# STM32H5F4xx register map
File version: 1.0
Registers are 32-bit, read-write, reset 0x0 unless marked. A register's access mark holds for its fields unless they carry their own. Offsets are from the block's base; [hi:lo] are bit positions; {n}, {i} and the like mark numbered series.

## HASH
Base 0x420C0400
Same registers: HASH_S 0x520C0400
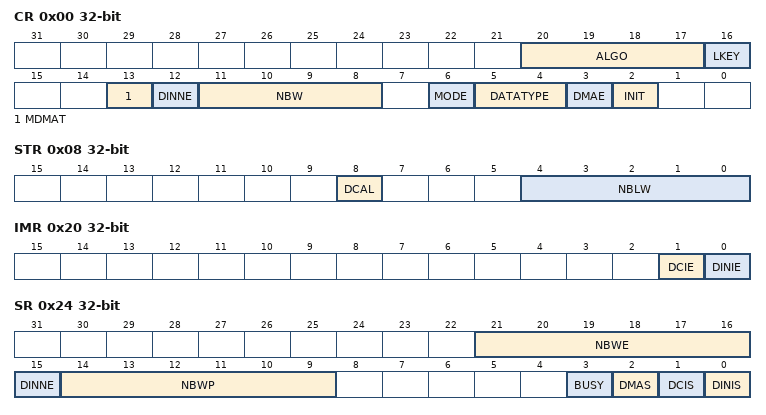
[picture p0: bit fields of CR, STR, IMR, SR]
0x00 CR — HASH control register
  [20:17] ALGO, [16] LKEY, [13] MDMAT, [12] DINNE, [11:8] NBW, [6] MODE, [5:4] DATATYPE, [3] DMAE, [2] INIT
0x04 DIN — HASH data input register
  [31:0] DATAIN
0x08 STR — HASH start register
  [8] DCAL, [4:0] NBLW
{0xC+4i} HRA{i} (i=0..4) — HASH digest registers
0x20 IMR — HASH interrupt enable register
  [1] DCIE, [0] DINIE
0x24 SR — HASH status register
  [21:16] NBWE, [15] DINNE, [14:9] NBWP, [3] BUSY, [2] DMAS, [1] DCIS, [0] DINIS
{0xF8+4i} CSR[{i}] (i=0..102)
{0x310+4i} HR{i} (i=0..41) — HASH digest registers

## RNG
Base 0x420C0800
Same registers: RNG_S 0x520C0800
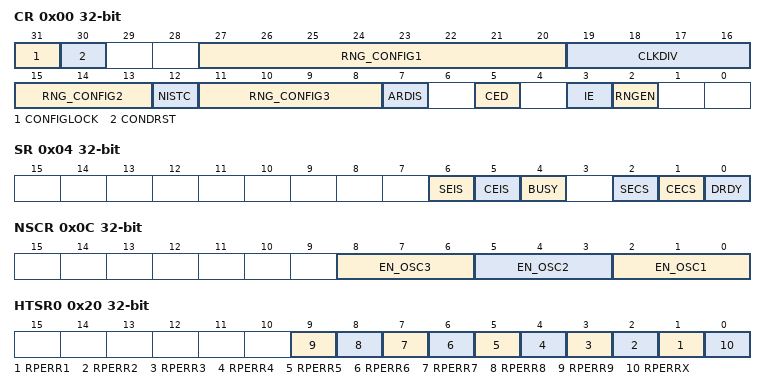
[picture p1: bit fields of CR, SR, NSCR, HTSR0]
0x00 CR — RNG control register
  [31] CONFIGLOCK — RNG configuration lock
  [30] CONDRST — Conditioning soft reset
  [27:20] RNG_CONFIG1 — RNG configuration 1
  [19:16] CLKDIV — Clock divider factor
    0=BY_1 (No clock division); 1=BY_2 (2 RNG clock cycles per internal RNG clock); 2=BY_4 (4 RNG clock cycles per internal RNG clock); 3=BY_8 (8 RNG clock cycles per internal RNG clock); 4=BY_16 (16 RNG clock cycles per internal RNG clock); 5=BY_32 (32 RNG clock cycles per internal RNG clock); 6=BY_64 (64 RNG clock cycles per internal RNG clock); 7=BY_128 (128 RNG clock cycles per internal RNG clock); 8=BY_256 (256 RNG clock cycles per internal RNG clock); 9=BY_512 (512 RNG clock cycles per internal RNG clock); 10=BY_1024 (1024 RNG clock cycles per internal RNG clock); 11=BY_2048 (2048 RNG clock cycles per internal RNG clock); 12=BY_4096 (4096 RNG clock cycles per internal RNG clock); 13=BY_8192 (8192 RNG clock cycles per internal RNG clock); 14=BY_16384 (16384 RNG clock cycles per internal RNG clock); 15=BY_32768 (32768 RNG clock cycles per internal RNG clock)
  [15:13] RNG_CONFIG2 — RNG configuration 2
  [12] NISTC — NIST custom
  [11:8] RNG_CONFIG3 — RNG configuration 3
  [7] ARDIS — Auto reset disable
  [5] CED — Clock error detection
  [3] IE — Interrupt enable
  [2] RNGEN — True random number generator enable
0x04 SR — RNG status register
  [6] SEIS, [5] CEIS, [4] BUSY, [2] SECS, [1] CECS, [0] DRDY
0x08 DR — RNG data register
0x0C NSCR — RNG noise source control register
  [8:6] EN_OSC3, [5:3] EN_OSC2, [2:0] EN_OSC1
{0x10+4i} HTCR{i} (i=0..3) — RNG health test configuration register
  [31:0] HTCFG
0x20 HTSR0 — RNG health test status register
  [n] RPERR{n} (n=1..9) — Repetitive error for oscillator i
  [0] RPERRX — Repetitive error after the XOR
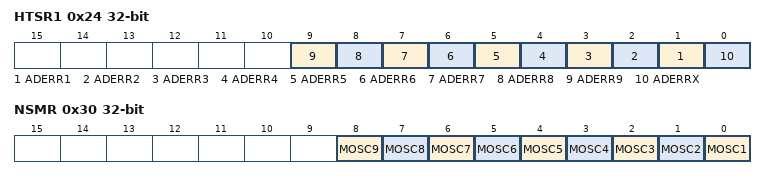
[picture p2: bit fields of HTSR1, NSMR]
0x24 HTSR1 — RNG health test status register
  [n] ADERR{n} (n=1..9) — Adaptative error for oscillator i
  [0] ADERRX — Adaptative error after the XOR
0x30 NSMR — RNG health test status register
  [n-1] MOSC{n} (n=1..9) — Mask oscillator i

## PKA
Base 0x420C2000
Same registers: PKA_S 0x520C2000
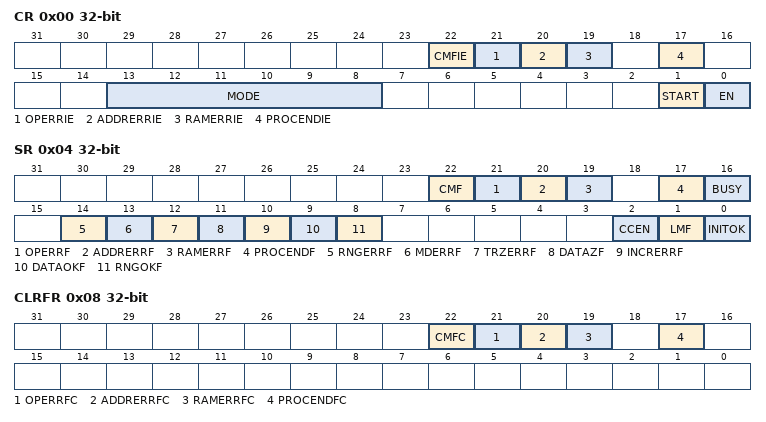
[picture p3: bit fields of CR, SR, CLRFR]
0x00 CR — PKA control register
  [22] CMFIE
  [21] OPERRIE — Operation Error interrupt enable
  [20] ADDRERRIE — Address error interrupt enable
  [19] RAMERRIE — RAM error interrupt enable
  [17] PROCENDIE — End of operation interrupt enable
  [13:8] MODE — MODE[5:0] PKA operation code
  [1] START — Start operation
  [0] EN — PKA enable
0x04 SR — PKA status register
  [22] CMF — Chaining mode flag
  [21] OPERRF — PKA operation Error flag
  [20] ADDRERRF — Address error flag
  [19] RAMERRF — PKA RAM error flag
  [17] PROCENDF — PKA end of operation flag
  [16] BUSY — PKA operation is in progress
  [14] RNGERRF — PKA RNG error flag
  [13] MDERRF — PKA Mode error flag
  [12] TRZERRF — PKA Trailing zeros error flag
  [11] DATAZF — PKA Data zeroed error flag
  [10] INCRERRF — PKA Increment error flag
  [9] DATAOKF — PKA Data OK flag
  [8] RNGOKF — PKA RNG OK flag
  [2] CCEN — PKA Coupling and chaining mode enable
  [1] LMF — PKA Limited mode flag
  [0] INITOK — PKA initialisation flag
0x08 CLRFR — PKA clear flag register
  [22] CMFC — Clear chaining mode flag
  [21] OPERRFC — Clear PKA operation Error flag
  [20] ADDRERRFC — Clear address error flag
  [19] RAMERRFC — Clear PKA RAM error flag
  [17] PROCENDFC — Clear PKA end of operation flag
{0x400+4i} RAM[{i}] (i=0..1333)
